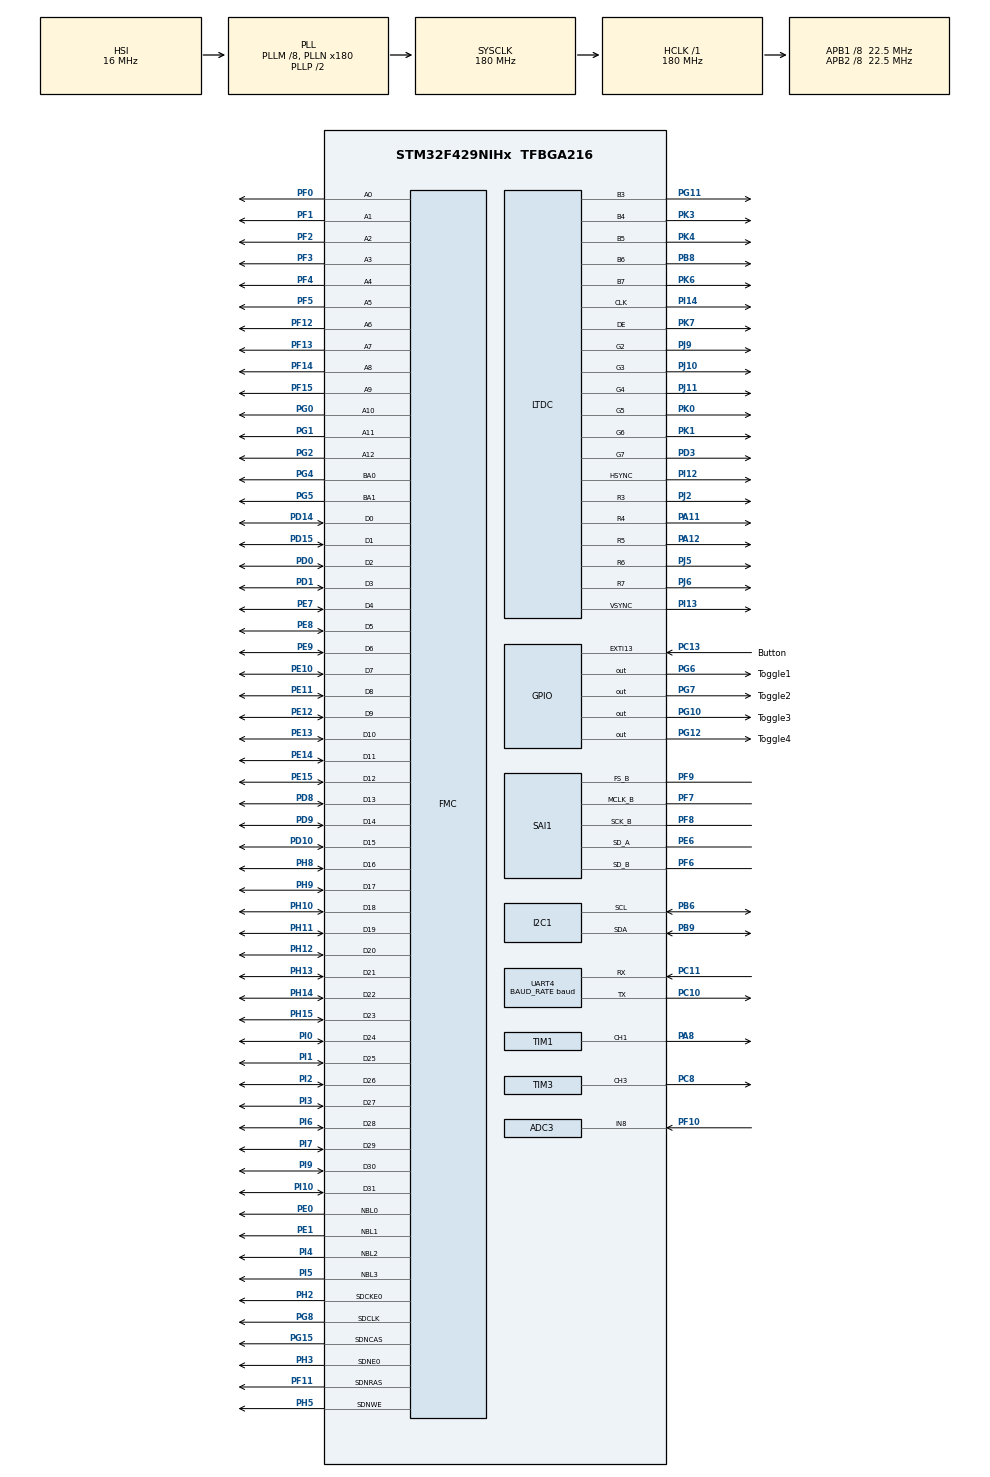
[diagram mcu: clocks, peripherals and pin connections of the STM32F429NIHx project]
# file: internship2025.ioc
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ADC3.Channel-0\#ChannelRegularConversion=ADC_CHANNEL_8
ADC3.DiscontinuousConvMode=ENABLE
ADC3.ExternalTrigConv=ADC_EXTERNALTRIGCONV_T1_CC1
ADC3.NbrOfConversionFlag=1
ADC3.Rank-0\#ChannelRegularConversion=1
ADC3.SamplingTime-0\#ChannelRegularConversion=ADC_SAMPLETIME_3CYCLES
ADC3.ScanConvMode=ENABLE
Dma.Request0=SAI1_A
Dma.Request1=SAI1_B
Dma.SAI1_A.0.Direction=DMA_PERIPH_TO_MEMORY
Dma.SAI1_A.0.FIFOMode=DMA_FIFOMODE_DISABLE
Dma.SAI1_A.0.Instance=DMA2_Stream1
Dma.SAI1_A.0.MemDataAlignment=DMA_MDATAALIGN_HALFWORD
Dma.SAI1_A.0.MemInc=DMA_MINC_ENABLE
Dma.SAI1_A.0.Mode=DMA_NORMAL
Dma.SAI1_A.0.PeriphDataAlignment=DMA_PDATAALIGN_HALFWORD
Dma.SAI1_A.0.PeriphInc=DMA_PINC_DISABLE
Dma.SAI1_A.0.Priority=DMA_PRIORITY_VERY_HIGH
Dma.SAI1_B.1.Direction=DMA_MEMORY_TO_PERIPH
Dma.SAI1_B.1.FIFOMode=DMA_FIFOMODE_DISABLE
Dma.SAI1_B.1.Instance=DMA2_Stream4
Dma.SAI1_B.1.MemDataAlignment=DMA_MDATAALIGN_HALFWORD
Dma.SAI1_B.1.MemInc=DMA_MINC_ENABLE
Dma.SAI1_B.1.Mode=DMA_NORMAL
Dma.SAI1_B.1.PeriphDataAlignment=DMA_PDATAALIGN_HALFWORD
Dma.SAI1_B.1.PeriphInc=DMA_PINC_DISABLE
Dma.SAI1_B.1.Priority=DMA_PRIORITY_VERY_HIGH
FMC.ColumnBitsNumber1=FMC_SDRAM_COLUMN_BITS_NUM_11
Mcu.Family=STM32F4
Mcu.Name=STM32F429NIHx
Mcu.Package=TFBGA216
Mcu.UserConstants=BAUD_RATE,115200
NVIC.ADC_IRQn=true\:2\:0\:true\:false\:true\:true\:true\:true
NVIC.DMA2_Stream1_IRQn=true\:0\:0\:false\:false\:true\:false\:true\:true
NVIC.DMA2_Stream4_IRQn=true\:0\:0\:false\:false\:true\:false\:true\:true
NVIC.EXTI15_10_IRQn=true\:2\:0\:true\:false\:true\:true\:true\:true
NVIC.PriorityGroup=NVIC_PRIORITYGROUP_4
NVIC.SAI1_IRQn=true\:0\:0\:false\:false\:true\:true\:true\:true
NVIC.TIM1_BRK_TIM9_IRQn=true\:1\:0\:true\:false\:true\:true\:true\:true
NVIC.TIM1_CC_IRQn=true\:2\:0\:true\:false\:true\:true\:true\:true
NVIC.TIM2_IRQn=true\:3\:0\:true\:false\:true\:true\:true\:true
NVIC.TIM4_IRQn=true\:3\:0\:true\:false\:true\:true\:true\:true
NVIC.TIM5_IRQn=true\:2\:0\:true\:false\:true\:true\:true\:true
NVIC.TIM6_DAC_IRQn=true\:3\:0\:true\:false\:true\:true\:true\:true
NVIC.UART4_IRQn=true\:10\:0\:true\:false\:true\:true\:true\:true
PA11.Mode=RGB565
PA11.Signal=LTDC_R4
PA12.Mode=RGB565
PA12.Signal=LTDC_R5
PA8.Signal=S_TIM1_CH1
PB6.Mode=I2C
PB6.Signal=I2C1_SCL
PB8.Mode=RGB565
PB8.Signal=LTDC_B6
PB9.Mode=I2C
PB9.Signal=I2C1_SDA
PC10.Mode=Asynchronous
PC10.Signal=UART4_TX
PC11.Mode=Asynchronous
PC11.Signal=UART4_RX
PC13.GPIO_Label=Button
PC13.GPIO_ModeDefaultEXTI=GPIO_MODE_IT_FALLING
PC13.GPIO_PuPd=GPIO_PULLUP
PC13.Signal=GPXTI13
PC8.Signal=S_TIM3_CH3
PD0.Signal=FMC_D2_DA2
PD1.Signal=FMC_D3_DA3
PD10.Signal=FMC_D15_DA15
PD14.Signal=FMC_D0_DA0
PD15.Signal=FMC_D1_DA1
PD3.Mode=RGB565
PD3.Signal=LTDC_G7
PD8.Signal=FMC_D13_DA13
PD9.Signal=FMC_D14_DA14
PE0.Signal=FMC_NBL0
PE1.Signal=FMC_NBL1
PE10.Signal=FMC_D7_DA7
PE11.Signal=FMC_D8_DA8
PE12.Signal=FMC_D9_DA9
PE13.Signal=FMC_D10_DA10
PE14.Signal=FMC_D11_DA11
PE15.Signal=FMC_D12_DA12
PE6.Mode=SAI_A_SyncSlave
PE6.Signal=SAI1_SD_A
PE7.Signal=FMC_D4_DA4
PE8.Signal=FMC_D5_DA5
PE9.Signal=FMC_D6_DA6
PF0.Signal=FMC_A0
PF1.Signal=FMC_A1
PF10.Mode=IN8
PF10.Signal=ADC3_IN8
PF11.Signal=FMC_SDNRAS
PF12.Signal=FMC_A6
PF13.Signal=FMC_A7
PF14.Signal=FMC_A8
PF15.Signal=FMC_A9
PF2.Signal=FMC_A2
PF3.Signal=FMC_A3
PF4.Signal=FMC_A4
PF5.Signal=FMC_A5
PF6.Mode=SAI_B_MasterWithClock
PF6.Signal=SAI1_SD_B
PF7.Mode=SAI_B_MasterWithClock
PF7.Signal=SAI1_MCLK_B
PF8.Mode=SAI_B_MasterWithClock
PF8.Signal=SAI1_SCK_B
PF9.Mode=SAI_B_MasterWithClock
PF9.Signal=SAI1_FS_B
PG0.Signal=FMC_A10
PG1.Signal=FMC_A11
PG10.GPIO_Label=Toggle3
PG10.Signal=GPIO_Output
PG11.Mode=RGB565
PG11.Signal=LTDC_B3
PG12.GPIO_Label=Toggle4
PG12.Signal=GPIO_Output
PG15.Signal=FMC_SDNCAS
PG2.Signal=FMC_A12
PG4.Signal=FMC_A14_BA0
PG5.Signal=FMC_A15_BA1
PG6.GPIO_Label=Toggle1
PG6.GPIO_PuPd=GPIO_PULLDOWN
PG6.PinState=GPIO_PIN_RESET
PG6.Signal=GPIO_Output
PG7.GPIO_Label=Toggle2
PG7.GPIO_PuPd=GPIO_PULLDOWN
PG7.GPIO_Speed=GPIO_SPEED_FREQ_VERY_HIGH
PG7.Signal=GPIO_Output
PG8.Signal=FMC_SDCLK
PH10.Signal=FMC_D18
PH11.Signal=FMC_D19
PH12.Signal=FMC_D20
PH13.Signal=FMC_D21
PH14.Signal=FMC_D22
PH15.Signal=FMC_D23
PH2.Mode=SdramChipSelect1_1
PH2.Signal=FMC_SDCKE0
PH3.Mode=SdramChipSelect1_1
PH3.Signal=FMC_SDNE0
PH5.Signal=FMC_SDNWE
PH8.Signal=FMC_D16
PH9.Signal=FMC_D17
PI0.Signal=FMC_D24
PI1.Signal=FMC_D25
PI10.Signal=FMC_D31
PI12.Mode=RGB565
PI12.Signal=LTDC_HSYNC
PI13.Mode=RGB565
PI13.Signal=LTDC_VSYNC
PI14.Mode=RGB565
PI14.Signal=LTDC_CLK
PI2.Signal=FMC_D26
PI3.Signal=FMC_D27
PI4.Signal=FMC_NBL2
PI5.Signal=FMC_NBL3
PI6.Signal=FMC_D28
PI7.Signal=FMC_D29
PI9.Signal=FMC_D30
PJ10.Mode=RGB565
PJ10.Signal=LTDC_G3
PJ11.Mode=RGB565
PJ11.Signal=LTDC_G4
PJ2.Mode=RGB565
PJ2.Signal=LTDC_R3
PJ5.Mode=RGB565
PJ5.Signal=LTDC_R6
PJ6.Mode=RGB565
PJ6.Signal=LTDC_R7
PJ9.Mode=RGB565
PJ9.Signal=LTDC_G2
PK0.Mode=RGB565
PK0.Signal=LTDC_G5
PK1.Mode=RGB565
PK1.Signal=LTDC_G6
PK3.Mode=RGB565
PK3.Signal=LTDC_B4
PK4.Mode=RGB565
PK4.Signal=LTDC_B5
PK6.Mode=RGB565
PK6.Signal=LTDC_B7
PK7.Mode=RGB565
PK7.Signal=LTDC_DE
ProjectManager.HeapSize=0x200
ProjectManager.StackSize=0x400
ProjectManager.TargetToolchain=STM32CubeIDE
RCC.48MHZClocksFreq_Value=90000000
RCC.AHBFreq_Value=180000000
RCC.APB1CLKDivider=RCC_HCLK_DIV8
RCC.APB1Freq_Value=22500000
RCC.APB1TimFreq_Value=45000000
RCC.APB2CLKDivider=RCC_HCLK_DIV8
RCC.APB2Freq_Value=22500000
RCC.APB2TimFreq_Value=45000000
RCC.CortexFreq_Value=180000000
RCC.HCLKFreq_Value=180000000
RCC.HSE_VALUE=25000000
RCC.HSI_VALUE=16000000
RCC.LSE_VALUE=32768
RCC.PLLI2SDivQ=32
RCC.PLLI2SN=194
RCC.PLLI2SQ=3
RCC.PLLM=8
RCC.PLLN=180
RCC.PLLSAIDivR=RCC_PLLSAIDIVR_8
RCC.PLLSAIN=77
RCC.PLLSAIQ=2
RCC.SAIClockSource_BlockA=SAI_CLKSOURCE_PLLI2S
RCC.SAIClockSource_BlockB=SAI_CLKSOURCE_PLLI2S
RCC.SYSCLKFreq_VALUE=180000000
RCC.SYSCLKSource=RCC_SYSCLKSOURCE_PLLCLK
RCC.VCOOutputFreq_Value=360000000
SAI1.ActiveFrameLength-SAI_A_SyncSlave=32
SAI1.ActiveFrameLength-SAI_B_MasterWithClock=32
SAI1.AudioFrequency-SAI_B_MasterWithClock=SAI_AUDIO_FREQUENCY_16K
SAI1.ClockSource-SAI_B_MasterWithClock=SAI_CLKSOURCE_PLLI2S
SAI1.DataSize-SAI_A_SyncSlave=SAI_DATASIZE_16
SAI1.DataSize-SAI_B_MasterWithClock=SAI_DATASIZE_16
SAI1.ErrorAudioFreq-SAI_B_MasterWithClock=-1.33 %
SAI1.FSDefinition-SAI_A_SyncSlave=SAI_FS_CHANNEL_IDENTIFICATION
SAI1.FSDefinition-SAI_B_MasterWithClock=SAI_FS_CHANNEL_IDENTIFICATION
SAI1.FSOffset-SAI_A_SyncSlave=SAI_FS_BEFOREFIRSTBIT
SAI1.FSOffset-SAI_B_MasterWithClock=SAI_FS_BEFOREFIRSTBIT
SAI1.FrameLength-SAI_A_SyncSlave=64
SAI1.FrameLength-SAI_B_MasterWithClock=64
SAI1.Instance-SAI_A_SyncSlave=SAI$Index_Block_A
SAI1.Instance-SAI_B_MasterWithClock=SAI$Index_Block_B
SAI1.MClockEnable-SAI_B_MasterWithClock=SAI_MASTERCLOCK_ENABLE
SAI1.RealAudioFreq-SAI_B_MasterWithClock=15.787 KHz
SAI1.SlotActive-SAI_A_SyncSlave=0x00000001
SAI1.SlotActive-SAI_B_MasterWithClock=0x00000005
SAI1.SlotNumber-SAI_A_SyncSlave=4
SAI1.SlotNumber-SAI_B_MasterWithClock=4
SAI1.Synchro_A=SAI_SYNCHRONOUS
SAI1.Synchro_B=SAI_ASYNCHRONOUS
SAI1.VirtualMode-SAI_A_SyncSlave=VM_SLAVE
SAI1.VirtualMode-SAI_B_MasterWithClock=VM_MASTER
SAI1.VirtualSlotActive-SAI_A_SyncSlave=SAI_SLOT_USERSETTING
SAI1.VirtualSlotActive-SAI_B_MasterWithClock=SAI_SLOT_USERSETTING
SAI1.VirtualSlotActive0-SAI_A_SyncSlave=true
SAI1.VirtualSlotActive0-SAI_B_MasterWithClock=true
SAI1.VirtualSlotActive2-SAI_B_MasterWithClock=true
SH.FMC_A0.0=FMC_A0,13b-sda1
SH.FMC_A1.0=FMC_A1,13b-sda1
SH.FMC_A10.0=FMC_A10,13b-sda1
SH.FMC_A11.0=FMC_A11,13b-sda1
SH.FMC_A12.0=FMC_A12,13b-sda1
SH.FMC_A14_BA0.0=FMC_BA0,FourSdramBanks1
SH.FMC_A15_BA1.0=FMC_BA1,FourSdramBanks1
SH.FMC_A2.0=FMC_A2,13b-sda1
SH.FMC_A3.0=FMC_A3,13b-sda1
SH.FMC_A4.0=FMC_A4,13b-sda1
SH.FMC_A5.0=FMC_A5,13b-sda1
SH.FMC_A6.0=FMC_A6,13b-sda1
SH.FMC_A7.0=FMC_A7,13b-sda1
SH.FMC_A8.0=FMC_A8,13b-sda1
SH.FMC_A9.0=FMC_A9,13b-sda1
SH.FMC_D0_DA0.0=FMC_D0,sd-32b-d1
SH.FMC_D10_DA10.0=FMC_D10,sd-32b-d1
SH.FMC_D11_DA11.0=FMC_D11,sd-32b-d1
SH.FMC_D12_DA12.0=FMC_D12,sd-32b-d1
SH.FMC_D13_DA13.0=FMC_D13,sd-32b-d1
SH.FMC_D14_DA14.0=FMC_D14,sd-32b-d1
SH.FMC_D15_DA15.0=FMC_D15,sd-32b-d1
SH.FMC_D16.0=FMC_D16,sd-32b-d1
SH.FMC_D17.0=FMC_D17,sd-32b-d1
SH.FMC_D18.0=FMC_D18,sd-32b-d1
SH.FMC_D19.0=FMC_D19,sd-32b-d1
SH.FMC_D1_DA1.0=FMC_D1,sd-32b-d1
SH.FMC_D20.0=FMC_D20,sd-32b-d1
SH.FMC_D21.0=FMC_D21,sd-32b-d1
SH.FMC_D22.0=FMC_D22,sd-32b-d1
SH.FMC_D23.0=FMC_D23,sd-32b-d1
SH.FMC_D24.0=FMC_D24,sd-32b-d1
SH.FMC_D25.0=FMC_D25,sd-32b-d1
SH.FMC_D26.0=FMC_D26,sd-32b-d1
SH.FMC_D27.0=FMC_D27,sd-32b-d1
SH.FMC_D28.0=FMC_D28,sd-32b-d1
SH.FMC_D29.0=FMC_D29,sd-32b-d1
SH.FMC_D2_DA2.0=FMC_D2,sd-32b-d1
SH.FMC_D30.0=FMC_D30,sd-32b-d1
SH.FMC_D31.0=FMC_D31,sd-32b-d1
SH.FMC_D3_DA3.0=FMC_D3,sd-32b-d1
SH.FMC_D4_DA4.0=FMC_D4,sd-32b-d1
SH.FMC_D5_DA5.0=FMC_D5,sd-32b-d1
SH.FMC_D6_DA6.0=FMC_D6,sd-32b-d1
SH.FMC_D7_DA7.0=FMC_D7,sd-32b-d1
SH.FMC_D8_DA8.0=FMC_D8,sd-32b-d1
SH.FMC_D9_DA9.0=FMC_D9,sd-32b-d1
SH.FMC_NBL0.0=FMC_NBL0,Sd4ByteEnable1
SH.FMC_NBL1.0=FMC_NBL1,Sd4ByteEnable1
SH.FMC_NBL2.0=FMC_NBL2,Sd4ByteEnable1
SH.FMC_NBL3.0=FMC_NBL3,Sd4ByteEnable1
SH.FMC_SDCLK.0=FMC_SDCLK,13b-sda1
SH.FMC_SDNCAS.0=FMC_SDNCAS,13b-sda1
SH.FMC_SDNRAS.0=FMC_SDNRAS,13b-sda1
SH.FMC_SDNWE.0=FMC_SDNWE,13b-sda1
SH.S_TIM1_CH1.0=TIM1_CH1,Output Compare1 CH1
SH.S_TIM3_CH3.0=TIM3_CH3,PWM Generation3 CH3
STMicroelectronics.X-CUBE-ALGOBUILD.1.4.0.LibraryCcDSPOoLibraryJjDSPOoLibrary=true
TIM1.Channel-Output\ Compare1\ CH1=TIM_CHANNEL_1
TIM1.OCMode_1=TIM_OCMODE_TOGGLE
TIM1.Period=5
TIM1.Prescaler=45000
TIM2.Period=10
TIM2.Prescaler=45000
TIM3.Channel-PWM\ Generation3\ CH3=TIM_CHANNEL_3
TIM3.Period=10000
TIM4.Period=1000
TIM4.Prescaler=45000
TIM5.Period=10
TIM5.Prescaler=45000
TIM6.Period=10000
TIM6.Prescaler=45000
TIM9.Period=10000
TIM9.Prescaler=45000
UART4.BaudRate=BAUD_RATE
UART4.Parity=PARITY_EVEN
UART4.VirtualMode=Asynchronous
UART4.WordLength=WORDLENGTH_9B
VP_DMA2D_VS_DMA2D.Mode=DMA2D_Activate
VP_STMicroelectronics.X-CUBE-ALGOBUILD_VS_DSPOoLibraryJjLibrary_1.4.0_1.4.0.Mode=DSPOoLibraryJjLibrary
VP_TIM1_VS_ClockSourceINT.Mode=Internal
VP_TIM2_VS_ClockSourceINT.Mode=Internal
VP_TIM3_VS_ClockSourceINT.Mode=Internal
VP_TIM4_VS_ClockSourceINT.Mode=Internal
VP_TIM5_VS_ClockSourceINT.Mode=Internal
VP_TIM6_VS_ClockSourceINT.Mode=Enable_Timer
VP_TIM9_VS_ClockSourceINT.Mode=Internal
board=custom

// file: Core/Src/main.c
/* USER CODE BEGIN Header */
/**
 ******************************************************************************
 * @file           : main.c
 * @brief          : Main program body
 ******************************************************************************
 * @attention
 *
 * Copyright (c) 2025 STMicroelectronics.
 * All rights reserved.
 *
 * This software is licensed under terms that can be found in the LICENSE file
 * in the root directory of this software component.
 * If no LICENSE file comes with this software, it is provided AS-IS.
 *
 ******************************************************************************
 */
/* USER CODE END Header */
#include "main.h"
#include "adc.h"
#include "dma.h"
#include "dma2d.h"
#include "fmc.h"
#include "gpio.h"
#include "i2c.h"
#include "ltdc.h"
#include "sai.h"
#include "tim.h"
#include "usart.h"

/* USER CODE BEGIN Includes */
#include "../../../Drivers/BSP/STM324x9I_EVAL/stm324x9i_eval_lcd.h"
#include "audio_processor.h"
#include "flow.h"
#include "queue.h"
#include "stdio.h"
#include "stm32f429xx.h"
#include "wm8994.h"
/* USER CODE END Includes */

void SystemClock_Config(void);
void PeriphCommonClock_Config(void);

int main(void)
{

    /* MCU Configuration--------------------------------------------------------*/

    /* Reset of all peripherals, Initializes the Flash interface and the Systick. */
    HAL_Init();

    /* Configure the system clock */
    SystemClock_Config();

    /* Configure the peripherals common clocks */
    PeriphCommonClock_Config();

    /* Initialize all configured peripherals */
    MX_GPIO_Init();
    MX_DMA_Init();
    MX_TIM5_Init();
    MX_TIM4_Init();
    MX_ADC3_Init();
    MX_TIM2_Init();
    MX_TIM1_Init();
    MX_TIM3_Init();
    MX_TIM9_Init();
    MX_TIM6_Init();
    MX_I2C1_Init();
    MX_SAI1_Init();
    MX_UART4_Init();
    MX_DMA2D_Init();
    MX_FMC_Init();
    MX_LTDC_Init();
    /* USER CODE BEGIN 2 */
    BSP_LCD_Init();
    BSP_LCD_LayerDefaultInit(1, LCD_FB_START_ADDRESS);
    BSP_LCD_SelectLayer(1);

    wm8994_t w;

    // We need the MCLK for codec configuration
    SAI1_Block_B->CR1 |= (1L << 16L);

    if (wm8994_init_driver(&w, &hi2c1, STM32429I_EVAL_WM8994_I2C_ADDR, &Error_Handler))
    {
        Error_Handler();
    }

    audio_proc_init(&hsai_BlockB1, &hsai_BlockA1);
    /* USER CODE END 2 */

    /* Infinite loop */
    /* USER CODE BEGIN WHILE */
    uint32_t current_command;
    while (1)
    {
        /* USER CODE END WHILE */

        /* USER CODE BEGIN 3 */
        if (command_queue_pop(&current_command))
        {
            uint8_t num = current_command - '0';
            if (num >= 1 && num <= 7)
            {
                state_t task = 1 << (num - 1);
                if ((task == BUTTON_INTERVAL) && !is_state_on(BUTTON_INTERVAL))
                {
                    uint32_t time;
                    stop_receiving();
                    printf("Recording time: ");
                    fflush(stdout);
                    time = read_int();
                    if (time != 0)
                    {
                        set_option(BUTTON_INTERVAL_RECORDING_TIME, time);
                    }
                    printf("\nLed on time: ");
                    fflush(stdout);
                    time = read_int();
                    if (time != 0)
                    {
                        set_option(BUTTON_INTERVAL_KEEP_LED_ON_TIME, time);
                    }
                    printf("\n");
                    start_receiving();
                }
                toggle_state(task);
                if (is_state_on(task))
                {
                    printf("Started option: %c\n", (uint8_t)current_command);
                }
                else
                {
                    printf("Stopped option: %c\n", (uint8_t)current_command);
                }
            }
            else
            {
                printf("Unknown option: %c\n", (uint8_t)current_command);
            }
        }

        if (is_state_on(AUDIO_MODULATOR))
        {
            audio_proc_process();
        }
    }
    /* USER CODE END 3 */
}

void SystemClock_Config(void)
{
    RCC_OscInitTypeDef RCC_OscInitStruct = { 0 };
    RCC_ClkInitTypeDef RCC_ClkInitStruct = { 0 };

    /** Macro to configure SAI1BlockB clock source selection
     */
    __HAL_RCC_SAI_BLOCKBCLKSOURCE_CONFIG(SAI_CLKSOURCE_PLLI2S);

    /** Macro to configure SAI1BlockA clock source selection
     */
    __HAL_RCC_SAI_BLOCKACLKSOURCE_CONFIG(SAI_CLKSOURCE_PLLI2S);

    /** Configure the main internal regulator output voltage
     */
    __HAL_RCC_PWR_CLK_ENABLE();
    __HAL_PWR_VOLTAGESCALING_CONFIG(PWR_REGULATOR_VOLTAGE_SCALE1);

    /** Initializes the RCC Oscillators according to the specified parameters
     * in the RCC_OscInitTypeDef structure.
     */
    RCC_OscInitStruct.OscillatorType = RCC_OSCILLATORTYPE_HSI;
    RCC_OscInitStruct.HSIState = RCC_HSI_ON;
    RCC_OscInitStruct.HSICalibrationValue = RCC_HSICALIBRATION_DEFAULT;
    RCC_OscInitStruct.PLL.PLLState = RCC_PLL_ON;
    RCC_OscInitStruct.PLL.PLLSource = RCC_PLLSOURCE_HSI;
    RCC_OscInitStruct.PLL.PLLM = 8;
    RCC_OscInitStruct.PLL.PLLN = 180;
    RCC_OscInitStruct.PLL.PLLP = RCC_PLLP_DIV2;
    RCC_OscInitStruct.PLL.PLLQ = 4;
    if (HAL_RCC_OscConfig(&RCC_OscInitStruct) != HAL_OK)
    {
        Error_Handler();
    }

    /** Activate the Over-Drive mode
     */
    if (HAL_PWREx_EnableOverDrive() != HAL_OK)
    {
        Error_Handler();
    }

    /** Initializes the CPU, AHB and APB buses clocks
     */
    RCC_ClkInitStruct.ClockType =
        RCC_CLOCKTYPE_HCLK | RCC_CLOCKTYPE_SYSCLK | RCC_CLOCKTYPE_PCLK1 | RCC_CLOCKTYPE_PCLK2;
    RCC_ClkInitStruct.SYSCLKSource = RCC_SYSCLKSOURCE_PLLCLK;
    RCC_ClkInitStruct.AHBCLKDivider = RCC_SYSCLK_DIV1;
    RCC_ClkInitStruct.APB1CLKDivider = RCC_HCLK_DIV8;
    RCC_ClkInitStruct.APB2CLKDivider = RCC_HCLK_DIV8;

    if (HAL_RCC_ClockConfig(&RCC_ClkInitStruct, FLASH_LATENCY_5) != HAL_OK)
    {
        Error_Handler();
    }
}

void PeriphCommonClock_Config(void)
{
    RCC_PeriphCLKInitTypeDef PeriphClkInitStruct = { 0 };

    /** Initializes the peripherals clock
     */
    PeriphClkInitStruct.PeriphClockSelection = RCC_PERIPHCLK_SAI_PLLI2S;
    PeriphClkInitStruct.PLLI2S.PLLI2SN = 194;
    PeriphClkInitStruct.PLLI2S.PLLI2SQ = 3;
    PeriphClkInitStruct.PLLI2SDivQ = 32;
    if (HAL_RCCEx_PeriphCLKConfig(&PeriphClkInitStruct) != HAL_OK)
    {
        Error_Handler();
    }
}

void Error_Handler(void)
{
    /* USER CODE BEGIN Error_Handler_Debug */
    /* User can add his own implementation to report the HAL error return state
     */
    __disable_irq();
    while (1)
    {
        HAL_GPIO_TogglePin(Toggle1_GPIO_Port, Toggle1_Pin);
        for (uint32_t i = 0; i < 100000; ++i);
    }
    /* USER CODE END Error_Handler_Debug */
}
#ifdef USE_FULL_ASSERT
/**
 * @brief  Reports the name of the source file and the source line number
 *         where the assert_param error has occurred.
 * @param  file: pointer to the source file name
 * @param  line: assert_param error line source number
 * @retval None
 */
void assert_failed(uint8_t *file, uint32_t line)
{
    /* USER CODE BEGIN 6 */
    /* User can add his own implementation to report the file name and line
       number, ex: printf("Wrong parameters value: file %s on line %d\r\n",
       file, line) */
    /* USER CODE END 6 */
}
#endif /* USE_FULL_ASSERT */
